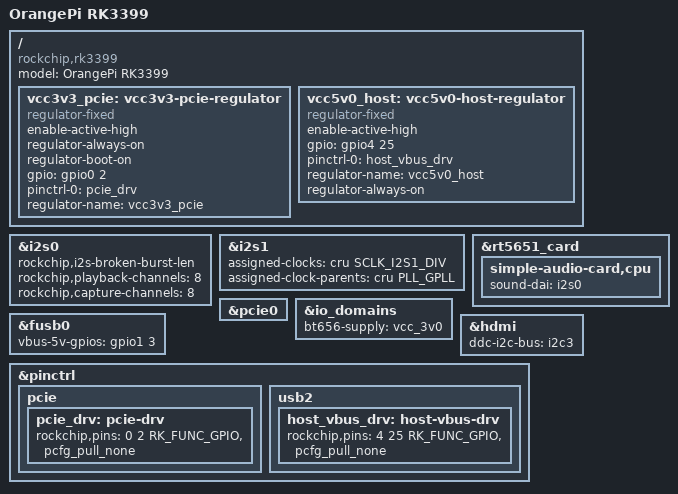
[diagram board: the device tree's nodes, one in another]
/*
 * Copyright (c) 2016 Fuzhou Rockchip Electronics Co., Ltd
 *
 * This file is dual-licensed: you can use it either under the terms
 * of the GPL or the X11 license, at your option. Note that this dual
 * licensing only applies to this file, and not this project as a
 * whole.
 *
 *  a) This file is free software; you can redistribute it and/or
 *     modify it under the terms of the GNU General Public License as
 *     published by the Free Software Foundation; either version 2 of the
 *     License, or (at your option) any later version.
 *
 *     This file is distributed in the hope that it will be useful,
 *     but WITHOUT ANY WARRANTY; without even the implied warranty of
 *     MERCHANTABILITY or FITNESS FOR A PARTICULAR PURPOSE.  See the
 *     GNU General Public License for more details.
 *
 * Or, alternatively,
 *
 *  b) Permission is hereby granted, free of charge, to any person
 *     obtaining a copy of this software and associated documentation
 *     files (the "Software"), to deal in the Software without
 *     restriction, including without limitation the rights to use,
 *     copy, modify, merge, publish, distribute, sublicense, and/or
 *     sell copies of the Software, and to permit persons to whom the
 *     Software is furnished to do so, subject to the following
 *     conditions:
 *
 *     The above copyright notice and this permission notice shall be
 *     included in all copies or substantial portions of the Software.
 *
 *     THE SOFTWARE IS PROVIDED "AS IS", WITHOUT WARRANTY OF ANY KIND,
 *     EXPRESS OR IMPLIED, INCLUDING BUT NOT LIMITED TO THE WARRANTIES
 *     OF MERCHANTABILITY, FITNESS FOR A PARTICULAR PURPOSE AND
 *     NONINFRINGEMENT. IN NO EVENT SHALL THE AUTHORS OR COPYRIGHT
 *     HOLDERS BE LIABLE FOR ANY CLAIM, DAMAGES OR OTHER LIABILITY,
 *     WHETHER IN AN ACTION OF CONTRACT, TORT OR OTHERWISE, ARISING
 *     FROM, OUT OF OR IN CONNECTION WITH THE SOFTWARE OR THE USE OR
 *     OTHER DEALINGS IN THE SOFTWARE.
 */

/dts-v1/;
#include "rk3399-orangepi-common.dtsi"

//#include "rk3399-orangepi-rkisp1.dtsi"
//#include "rk3399-orangepi-lcd.dtsi"

/ {
	model = "OrangePi RK3399";
	compatible = "rockchip,rk3399";

	vcc3v3_pcie: vcc3v3-pcie-regulator {
		compatible = "regulator-fixed";
		enable-active-high;
		regulator-always-on;
		regulator-boot-on;
		gpio = <&gpio0 2 GPIO_ACTIVE_HIGH>;
		pinctrl-names = "default";
		pinctrl-0 = <&pcie_drv>;
		regulator-name = "vcc3v3_pcie";
	};

        vcc5v0_host: vcc5v0-host-regulator {
		compatible = "regulator-fixed";
		enable-active-high;
		gpio = <&gpio4 25 GPIO_ACTIVE_HIGH>;
		pinctrl-names = "default";
		pinctrl-0 = <&host_vbus_drv>;
		regulator-name = "vcc5v0_host";
		regulator-always-on;
	};
};

&i2s0 {
        status = "okay";
        rockchip,i2s-broken-burst-len;
        rockchip,playback-channels = <8>;
        rockchip,capture-channels = <8>;
        #sound-dai-cells = <0>;
};

&i2s1 {
        assigned-clocks = <&cru SCLK_I2S1_DIV>;
        assigned-clock-parents = <&cru PLL_GPLL>;
};

&rt5651_card {
        simple-audio-card,cpu {
                sound-dai = <&i2s0>;
        };
};

&pcie0 {
	status = "okay";
};

&io_domains {
        status = "okay";
        bt656-supply = <&vcc_3v0>;           /* bt656_gpio2ab_ms */
};

&fusb0 {
	vbus-5v-gpios = <&gpio1 3 GPIO_ACTIVE_HIGH>;
};

&hdmi {
	ddc-i2c-bus = <&i2c3>;
};


&pinctrl {
	pcie {
		pcie_drv: pcie-drv {
		rockchip,pins =
			<0 2 RK_FUNC_GPIO &pcfg_pull_none>;
		};
	};
	usb2 {
		host_vbus_drv: host-vbus-drv {
			rockchip,pins =
				<4 25 RK_FUNC_GPIO &pcfg_pull_none>;
		};
	};

};
